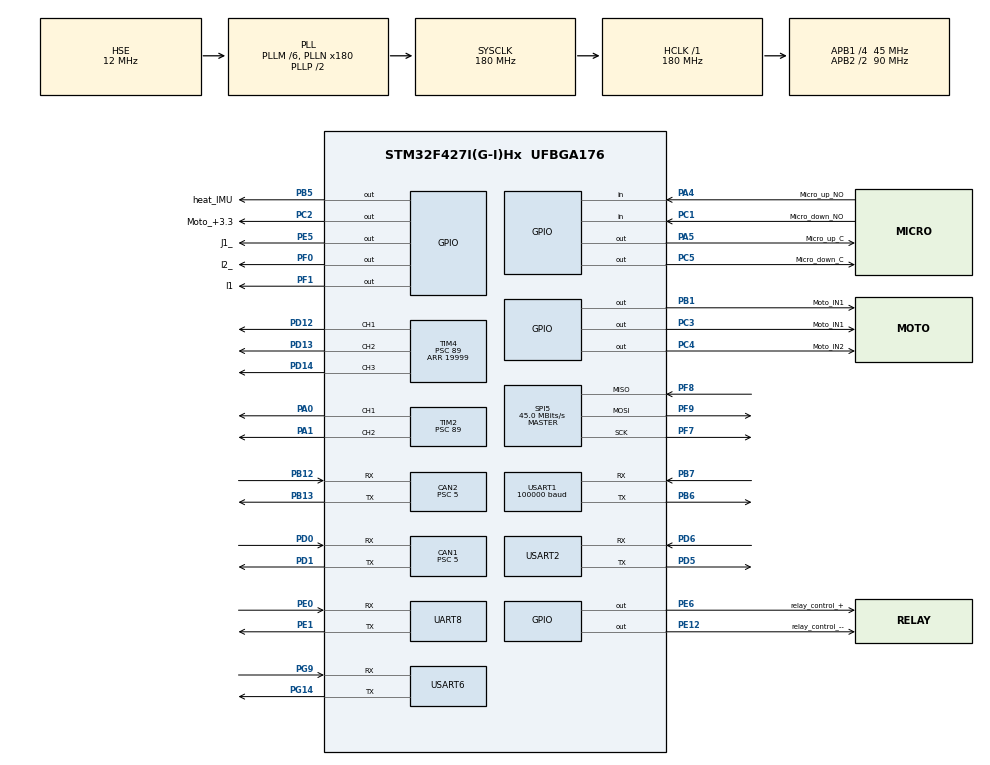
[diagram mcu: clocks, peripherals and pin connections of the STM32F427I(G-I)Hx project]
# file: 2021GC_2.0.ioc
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CAN1.ABOM=ENABLE
CAN1.BS1=CAN_BS1_3TQ
CAN1.BS2=CAN_BS2_5TQ
CAN1.CalculateBaudRate=1000000
CAN1.CalculateTimeBit=999.99
CAN1.CalculateTimeQuantum=111.11111111111111
CAN1.Prescaler=5
CAN2.ABOM=ENABLE
CAN2.BS1=CAN_BS1_3TQ
CAN2.BS2=CAN_BS2_5TQ
CAN2.CalculateBaudRate=1000000
CAN2.CalculateTimeBit=999.99
CAN2.CalculateTimeQuantum=111.11111111111111
CAN2.Prescaler=5
Dma.Request0=USART1_RX
Dma.USART1_RX.0.Direction=DMA_PERIPH_TO_MEMORY
Dma.USART1_RX.0.FIFOMode=DMA_FIFOMODE_DISABLE
Dma.USART1_RX.0.Instance=DMA2_Stream2
Dma.USART1_RX.0.MemDataAlignment=DMA_MDATAALIGN_BYTE
Dma.USART1_RX.0.MemInc=DMA_MINC_ENABLE
Dma.USART1_RX.0.Mode=DMA_NORMAL
Dma.USART1_RX.0.PeriphDataAlignment=DMA_PDATAALIGN_BYTE
Dma.USART1_RX.0.PeriphInc=DMA_PINC_DISABLE
Dma.USART1_RX.0.Priority=DMA_PRIORITY_VERY_HIGH
FREERTOS.Tasks01=Chassis,0,128,Chassis_Task,Default,NULL,Dynamic,NULL,NULL;Get,0,128,Get_task,Default,NULL,Dynamic,NULL,NULL;Other,0,128,Other_task,Default,NULL,Dynamic,NULL,NULL;Key,0,128,Key_Task,Default,NULL,Dynamic,NULL,NULL
Mcu.Family=STM32F4
Mcu.Name=STM32F427I(G-I)Hx
Mcu.Package=UFBGA176
NVIC.CAN1_RX0_IRQn=true\:5\:0\:false\:false\:true\:false\:true\:true
NVIC.CAN1_TX_IRQn=true\:5\:0\:false\:false\:true\:false\:true\:true
NVIC.CAN2_RX0_IRQn=true\:5\:0\:false\:false\:true\:false\:true\:true
NVIC.CAN2_TX_IRQn=true\:5\:0\:false\:false\:true\:false\:true\:true
NVIC.DMA2_Stream2_IRQn=true\:5\:0\:false\:false\:true\:true\:false\:true
NVIC.PriorityGroup=NVIC_PRIORITYGROUP_4
NVIC.TIM8_UP_TIM13_IRQn=true\:0\:0\:false\:false\:true\:false\:false\:true
NVIC.TimeBase=TIM8_UP_TIM13_IRQn
NVIC.TimeBaseIP=TIM8
NVIC.USART1_IRQn=true\:5\:0\:false\:false\:true\:false\:true\:true
NVIC.USART2_IRQn=true\:5\:0\:false\:false\:true\:true\:true\:true
NVIC.USART6_IRQn=true\:5\:0\:false\:false\:true\:true\:true\:true
PA0/WKUP.Signal=S_TIM2_CH1_ETR
PA1.Signal=S_TIM2_CH2
PA13.Mode=Serial_Wire
PA13.Signal=SYS_JTMS-SWDIO
PA14.Mode=Serial_Wire
PA14.Signal=SYS_JTCK-SWCLK
PA4.GPIO_Label=Micro_up_NO
PA4.GPIO_PuPd=GPIO_PULLDOWN
PA4.Signal=GPIO_Input
PA5.GPIO_Label=Micro_up_C
PA5.GPIO_PuPd=GPIO_PULLUP
PA5.GPIO_Speed=GPIO_SPEED_FREQ_VERY_HIGH
PA5.PinState=GPIO_PIN_SET
PA5.Signal=GPIO_Output
PB1.GPIO_Label=Moto_IN1
PB1.Signal=GPIO_Output
PB12.Mode=CAN_Activate
PB12.Signal=CAN2_RX
PB13.Mode=CAN_Activate
PB13.Signal=CAN2_TX
PB5.GPIO_Label=heat_IMU
PB5.GPIO_PuPd=GPIO_PULLUP
PB5.PinState=GPIO_PIN_SET
PB5.Signal=GPIO_Output
PB6.Mode=Asynchronous
PB6.Signal=USART1_TX
PB7.Mode=Asynchronous
PB7.Signal=USART1_RX
PC1.GPIO_Label=Micro_down_NO
PC1.GPIO_PuPd=GPIO_PULLDOWN
PC1.Signal=GPIO_Input
PC14/OSC32_IN.Mode=LSE-External-Oscillator
PC14/OSC32_IN.Signal=RCC_OSC32_IN
PC15/OSC32_OUT.Mode=LSE-External-Oscillator
PC15/OSC32_OUT.Signal=RCC_OSC32_OUT
PC2.GPIO_Label=Moto_+3.3
PC2.GPIO_PuPd=GPIO_PULLUP
PC2.GPIO_Speed=GPIO_SPEED_FREQ_VERY_HIGH
PC2.PinState=GPIO_PIN_SET
PC2.Signal=GPIO_Output
PC3.GPIO_Label=Moto_IN1
PC3.GPIO_PuPd=GPIO_PULLDOWN
PC3.Signal=GPIO_Output
PC4.GPIO_Label=Moto_IN2
PC4.GPIO_PuPd=GPIO_PULLDOWN
PC4.Signal=GPIO_Output
PC5.GPIO_Label=Micro_down_C
PC5.GPIO_PuPd=GPIO_PULLUP
PC5.GPIO_Speed=GPIO_SPEED_FREQ_VERY_HIGH
PC5.PinState=GPIO_PIN_SET
PC5.Signal=GPIO_Output
PD0.Mode=CAN_Activate
PD0.Signal=CAN1_RX
PD1.Mode=CAN_Activate
PD1.Signal=CAN1_TX
PD12.Signal=S_TIM4_CH1
PD13.Signal=S_TIM4_CH2
PD14.Signal=S_TIM4_CH3
PD15.Signal=S_TIM4_CH4
PD5.Mode=Asynchronous
PD5.Signal=USART2_TX
PD6.Mode=Asynchronous
PD6.Signal=USART2_RX
PE0.Mode=Asynchronous
PE0.Signal=UART8_RX
PE1.Mode=Asynchronous
PE1.Signal=UART8_TX
PE12.GPIO_Label=relay_control_--
PE12.GPIO_Speed=GPIO_SPEED_FREQ_LOW
PE12.Signal=GPIO_Output
PE5.GPIO_Label=J1_
PE5.GPIO_PuPd=GPIO_PULLDOWN
PE5.GPIO_Speed=GPIO_SPEED_FREQ_MEDIUM
PE5.Signal=GPIO_Output
PE6.GPIO_Label=relay_control_+
PE6.GPIO_PuPd=GPIO_PULLUP
PE6.PinState=GPIO_PIN_SET
PE6.Signal=GPIO_Output
PF0.GPIO_Label=I2_
PF0.GPIO_PuPd=GPIO_PULLDOWN
PF0.GPIO_Speed=GPIO_SPEED_FREQ_LOW
PF0.Signal=GPIO_Output
PF1.GPIO_Label=I1
PF1.GPIO_PuPd=GPIO_PULLDOWN
PF1.GPIO_Speed=GPIO_SPEED_FREQ_LOW
PF1.Signal=GPIO_Output
PF7.Mode=Full_Duplex_Master
PF7.Signal=SPI5_SCK
PF8.Mode=Full_Duplex_Master
PF8.Signal=SPI5_MISO
PF9.Mode=Full_Duplex_Master
PF9.Signal=SPI5_MOSI
PG14.Mode=Asynchronous
PG14.Signal=USART6_TX
PG9.Mode=Asynchronous
PG9.Signal=USART6_RX
PH0/OSC_IN.Mode=HSE-External-Oscillator
PH0/OSC_IN.Signal=RCC_OSC_IN
PH1/OSC_OUT.Mode=HSE-External-Oscillator
PH1/OSC_OUT.Signal=RCC_OSC_OUT
ProjectManager.HeapSize=0x200
ProjectManager.StackSize=0x400
ProjectManager.TargetToolchain=MDK-ARM V5
RCC.48MHZClocksFreq_Value=90000000
RCC.AHBFreq_Value=180000000
RCC.APB1CLKDivider=RCC_HCLK_DIV4
RCC.APB1Freq_Value=45000000
RCC.APB1TimFreq_Value=90000000
RCC.APB2CLKDivider=RCC_HCLK_DIV2
RCC.APB2Freq_Value=90000000
RCC.APB2TimFreq_Value=180000000
RCC.CortexFreq_Value=180000000
RCC.HCLKFreq_Value=180000000
RCC.HSE_VALUE=12000000
RCC.HSI_VALUE=16000000
RCC.PLLM=6
RCC.PLLN=180
RCC.PLLSourceVirtual=RCC_PLLSOURCE_HSE
RCC.SYSCLKFreq_VALUE=180000000
RCC.SYSCLKSource=RCC_SYSCLKSOURCE_PLLCLK
RCC.VCOOutputFreq_Value=360000000
SH.S_TIM2_CH1_ETR.0=TIM2_CH1,PWM Generation1 CH1
SH.S_TIM2_CH2.0=TIM2_CH2,PWM Generation2 CH2
SH.S_TIM4_CH1.0=TIM4_CH1,PWM Generation1 CH1
SH.S_TIM4_CH2.0=TIM4_CH2,PWM Generation2 CH2
SH.S_TIM4_CH3.0=TIM4_CH3,PWM Generation3 CH3
SH.S_TIM4_CH4.0=TIM4_CH4
SPI5.CalculateBaudRate=45.0 MBits/s
SPI5.Direction=SPI_DIRECTION_2LINES
SPI5.Mode=SPI_MODE_MASTER
SPI5.VirtualType=VM_MASTER
TIM2.AutoReloadPreload=TIM_AUTORELOAD_PRELOAD_ENABLE
TIM2.Channel-PWM\ Generation1\ CH1=TIM_CHANNEL_1
TIM2.Channel-PWM\ Generation2\ CH2=TIM_CHANNEL_2
TIM2.Period=19999
TIM2.Prescaler=89
TIM4.AutoReloadPreload=TIM_AUTORELOAD_PRELOAD_ENABLE
TIM4.Channel-PWM\ Generation1\ CH1=TIM_CHANNEL_1
TIM4.Channel-PWM\ Generation2\ CH2=TIM_CHANNEL_2
TIM4.Channel-PWM\ Generation3\ CH3=TIM_CHANNEL_3
TIM4.Period=19999
TIM4.Prescaler=89
UART8.VirtualMode=Asynchronous
USART1.BaudRate=100000
USART1.Parity=PARITY_EVEN
USART1.VirtualMode=VM_ASYNC
USART2.VirtualMode=VM_ASYNC
USART6.VirtualMode=VM_ASYNC
VP_FREERTOS_VS_CMSIS_V1.Mode=CMSIS_V1
VP_SYS_VS_tim8.Mode=TIM8
VP_TIM2_VS_ClockSourceINT.Mode=Internal
VP_TIM4_VS_ClockSourceINT.Mode=Internal
board=custom

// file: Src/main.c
/* USER CODE BEGIN Header */
/**
  ******************************************************************************
  * @file           : main.c
  * @brief          : Main program body
  ******************************************************************************
  * @attention
  *
  * <h2><center>&copy; Copyright (c) 2021 STMicroelectronics.
  * All rights reserved.</center></h2>
  *
  * This software component is licensed by ST under Ultimate Liberty license
  * SLA0044, the "License"; You may not use this file except in compliance with
  * the License. You may obtain a copy of the License at:
  *                             www.st.com/SLA0044
  *
  ******************************************************************************
  */
/* USER CODE END Header */
#include "main.h"
#include "cmsis_os.h"
#include "can.h"
#include "dma.h"
#include "spi.h"
#include "tim.h"
#include "usart.h"
#include "gpio.h"

/* USER CODE BEGIN Includes */
#include "Centre.h"
/* USER CODE END Includes */

void SystemClock_Config(void);
void MX_FREERTOS_Init(void);

int main(void)
{

  /* MCU Configuration--------------------------------------------------------*/

  /* Reset of all peripherals, Initializes the Flash interface and the Systick. */
  HAL_Init();

  /* Configure the system clock */
  SystemClock_Config();

  /* Initialize all configured peripherals */
  MX_GPIO_Init();
  MX_DMA_Init();
  MX_TIM4_Init();
  MX_CAN1_Init();
  MX_CAN2_Init();
  MX_USART1_UART_Init();
  MX_USART6_UART_Init();
  MX_TIM2_Init();
  MX_USART2_UART_Init();
  MX_UART8_Init();
  MX_SPI5_Init();
  /* USER CODE BEGIN 2 */
	base_init();
	HAL_Delay(1);
	task_init();
  /* USER CODE END 2 */

  /* Call init function for freertos objects (in freertos.c) */
  MX_FREERTOS_Init();
  /* Start scheduler */
  osKernelStart();

  /* We should never get here as control is now taken by the scheduler */
  /* Infinite loop */
  while (1)
  {

  }
}

void SystemClock_Config(void)
{
  RCC_OscInitTypeDef RCC_OscInitStruct = {0};
  RCC_ClkInitTypeDef RCC_ClkInitStruct = {0};

  /** Configure the main internal regulator output voltage
  */
  __HAL_RCC_PWR_CLK_ENABLE();
  __HAL_PWR_VOLTAGESCALING_CONFIG(PWR_REGULATOR_VOLTAGE_SCALE1);
  /** Initializes the RCC Oscillators according to the specified parameters
  * in the RCC_OscInitTypeDef structure.
  */
  RCC_OscInitStruct.OscillatorType = RCC_OSCILLATORTYPE_HSE;
  RCC_OscInitStruct.HSEState = RCC_HSE_ON;
  RCC_OscInitStruct.PLL.PLLState = RCC_PLL_ON;
  RCC_OscInitStruct.PLL.PLLSource = RCC_PLLSOURCE_HSE;
  RCC_OscInitStruct.PLL.PLLM = 6;
  RCC_OscInitStruct.PLL.PLLN = 180;
  RCC_OscInitStruct.PLL.PLLP = RCC_PLLP_DIV2;
  RCC_OscInitStruct.PLL.PLLQ = 4;
  if (HAL_RCC_OscConfig(&RCC_OscInitStruct) != HAL_OK)
  {
    Error_Handler();
  }
  /** Activate the Over-Drive mode
  */
  if (HAL_PWREx_EnableOverDrive() != HAL_OK)
  {
    Error_Handler();
  }
  /** Initializes the CPU, AHB and APB buses clocks
  */
  RCC_ClkInitStruct.ClockType = RCC_CLOCKTYPE_HCLK|RCC_CLOCKTYPE_SYSCLK
                              |RCC_CLOCKTYPE_PCLK1|RCC_CLOCKTYPE_PCLK2;
  RCC_ClkInitStruct.SYSCLKSource = RCC_SYSCLKSOURCE_PLLCLK;
  RCC_ClkInitStruct.AHBCLKDivider = RCC_SYSCLK_DIV1;
  RCC_ClkInitStruct.APB1CLKDivider = RCC_HCLK_DIV4;
  RCC_ClkInitStruct.APB2CLKDivider = RCC_HCLK_DIV2;

  if (HAL_RCC_ClockConfig(&RCC_ClkInitStruct, FLASH_LATENCY_5) != HAL_OK)
  {
    Error_Handler();
  }
}

 /**
  * @brief  Period elapsed callback in non blocking mode
  * @note   This function is called  when TIM8 interrupt took place, inside
  * HAL_TIM_IRQHandler(). It makes a direct call to HAL_IncTick() to increment
  * a global variable "uwTick" used as application time base.
  * @param  htim : TIM handle
  * @retval None
  */
void HAL_TIM_PeriodElapsedCallback(TIM_HandleTypeDef *htim)
{
  if (htim->Instance == TIM8) {
    HAL_IncTick();
  }
}

void Error_Handler(void)
{
}

/************************ (C) COPYRIGHT STMicroelectronics *****END OF FILE****/

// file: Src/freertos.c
/* USER CODE BEGIN Header */
/**
  ******************************************************************************
  * File Name          : freertos.c
  * Description        : Code for freertos applications
  ******************************************************************************
  * @attention
  *
  * <h2><center>&copy; Copyright (c) 2021 STMicroelectronics.
  * All rights reserved.</center></h2>
  *
  * This software component is licensed by ST under Ultimate Liberty license
  * SLA0044, the "License"; You may not use this file except in compliance with
  * the License. You may obtain a copy of the License at:
  *                             www.st.com/SLA0044
  *
  ******************************************************************************
  */
/* USER CODE END Header */

#include "FreeRTOS.h"
#include "task.h"
#include "main.h"
#include "cmsis_os.h"

/* USER CODE BEGIN Includes */
#include "Centre.h"
/* USER CODE END Includes */

osThreadId ChassisHandle;
osThreadId GetHandle;
osThreadId OtherHandle;
osThreadId KeyHandle;

void Chassis_Task(void const * argument);
void Get_task(void const * argument);
void Other_task(void const * argument);
void Key_Task(void const * argument);

void MX_FREERTOS_Init(void); /* (MISRA C 2004 rule 8.1) */

/* GetIdleTaskMemory prototype (linked to static allocation support) */
void vApplicationGetIdleTaskMemory( StaticTask_t **ppxIdleTaskTCBBuffer, StackType_t **ppxIdleTaskStackBuffer, uint32_t *pulIdleTaskStackSize );

/* USER CODE BEGIN GET_IDLE_TASK_MEMORY */
static StaticTask_t xIdleTaskTCBBuffer;
static StackType_t xIdleStack[configMINIMAL_STACK_SIZE];

void vApplicationGetIdleTaskMemory( StaticTask_t **ppxIdleTaskTCBBuffer, StackType_t **ppxIdleTaskStackBuffer, uint32_t *pulIdleTaskStackSize )
{
  *ppxIdleTaskTCBBuffer = &xIdleTaskTCBBuffer;
  *ppxIdleTaskStackBuffer = &xIdleStack[0];
  *pulIdleTaskStackSize = configMINIMAL_STACK_SIZE;
  /* place for user code */
}
/* USER CODE END GET_IDLE_TASK_MEMORY */

void MX_FREERTOS_Init(void) {

  /* Create the thread(s) */
  /* definition and creation of Chassis */
  osThreadDef(Chassis, Chassis_Task, osPriorityNormal, 0, 128);
  ChassisHandle = osThreadCreate(osThread(Chassis), NULL);

  /* definition and creation of Get */
  osThreadDef(Get, Get_task, osPriorityNormal, 0, 128);
  GetHandle = osThreadCreate(osThread(Get), NULL);

  /* definition and creation of Other */
  osThreadDef(Other, Other_task, osPriorityNormal, 0, 128);
  OtherHandle = osThreadCreate(osThread(Other), NULL);

  /* definition and creation of Key */
  osThreadDef(Key, Key_Task, osPriorityNormal, 0, 128);
  KeyHandle = osThreadCreate(osThread(Key), NULL);

}

void Chassis_Task(void const * argument)
{
  /* USER CODE BEGIN Chassis_Task */
  /* Infinite loop */
  for(;;)
  {
	chassis_all_task();
    osDelay(1);
  }
  /* USER CODE END Chassis_Task */
}

void Get_task(void const * argument)
{
  /* USER CODE BEGIN Get_task */
  /* Infinite loop */
  for(;;)
  {
	Get_all_task();
    osDelay(1);
  }
  /* USER CODE END Get_task */
}

void Other_task(void const * argument)
{
  /* USER CODE BEGIN Other_task */
  /* Infinite loop */
  for(;;)
  {
	Other_all_task();
    osDelay(1);
  }
  /* USER CODE END Other_task */
}

void Key_Task(void const * argument)
{
  /* USER CODE BEGIN Key_Task */
  /* Infinite loop */
  for(;;)
  {
	key_all_task();
    osDelay(1);
  }
  /* USER CODE END Key_Task */
}

/************************ (C) COPYRIGHT STMicroelectronics *****END OF FILE****/
